# MSP432P401R register map
Vendor: Texas Instruments; File version: 3.220
Registers are 32-bit, read-write, reset 0x0 unless marked. A register's access mark holds for its fields unless they carry their own. Offsets are from the block's base; [hi:lo] are bit positions; {n}, {i} and the like mark numbered series.

## PSS
Base 0x40010800
0x00 PSSKEY reset 0xA596 — Key Register
  [15:0] PSSKEY — PSS control key
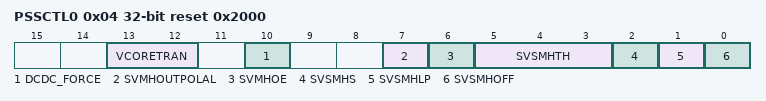
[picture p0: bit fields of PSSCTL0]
0x04 PSSCTL0 reset 0x2000 — Control 0 Register
  [13:12] VCORETRAN — Controls core voltage level transition time
    0=32 s / 100 mV; 1=64 s / 100 mV; 2=128 s / 100 mV (default); 3=256 s / 100 mV
  [10] DCDC_FORCE — Force DC-DC regulator operation
    0=DC-DC regulator operation not forced. Automatic fail-safe mechanism switches the core voltage regulator from DC-DC to LDO when the supply voltage falls below the minimum supply voltage necessary for DC-DC operation.; 1=DC-DC regulator operation forced. Automatic fail-safe mechanism is disabled and device continues to operate out of DC-DC regulator.
  [7] SVMHOUTPOLAL — SVMHOUT pin polarity active low
    0=SVMHOUT is active high. An error condition is signaled by a 1 at the SVMHOUT pin; 1=SVMHOUT is active low. An error condition is signaled by a 0 at the SVMHOUT pin
  [6] SVMHOE — SVSM high-side output enable
    0=SVSMHIFG bit is not output; 1=SVSMHIFG bit is output to the device SVMHOUT pin. The device-specific port logic must be configured accordingly
  [5:3] SVSMHTH — SVSM high-side reset voltage level
  [2] SVSMHS — Supply supervisor or monitor selection for the high-side
    0=Configure as SVSH; 1=Configure as SVMH
  [1] SVSMHLP — SVSM high-side low power normal performance mode
    0=Full performance mode. See the device-specific data sheet for response times.; 1=Low power normal performance mode in LPM3, LPM4, and LPMx.5, full performance in all other modes. See the device-specific data sheet for response times.
  [0] SVSMHOFF — SVSM high-side off
    0=The SVSMH is on; 1=The SVSMH is off
0x34 PSSIE — Interrupt Enable Register
  [1] SVSMHIE — High-side SVSM interrupt enable
    0=Interrupt disabled; 1=Interrupt enabled
0x38 PSSIFG ro — Interrupt Flag Register
  [1] SVSMHIFG — High-side SVSM interrupt flag
    on read: 0=No interrupt pending; 1=Interrupt due to SVSMH
0x3C PSSCLRIFG — Clear Interrupt Flag Register
  [1] CLRSVSMHIFG wo — SVSMH clear interrupt flag
    on write: 0=No effect; 1=Clear pending interrupt flag

## ITM
Base 0xE0000000
{0x0+4i} ITM_STIM{i} (i=0..31) — ITM Stimulus Port {i}
0xE00 ITM_TER — ITM Trace Enable Register
  [31:0] STIMENA — Bit mask to enable tracing on ITM stimulus ports. One bit per stimulus port.
0xE40 ITM_TPR — ITM Trace Privilege Register
  [3:0] PRIVMASK — Bit mask to enable tracing on ITM stimulus ports: bit [0] = stimulus ports [7:0], bit [1] = stimulus ports [15:8], bit [2] = stimulus ports [23:16], bit [3] = stimulus ports [31:24].
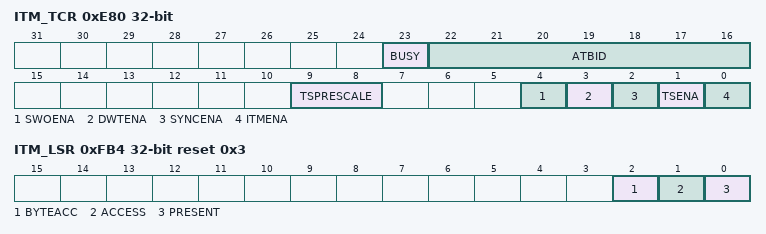
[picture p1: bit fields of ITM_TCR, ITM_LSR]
0xE80 ITM_TCR — ITM Trace Control Register
  [23] BUSY — Set when ITM events present and being drained.
  [22:16] ATBID — ATB ID for CoreSight system.
  [9:8] TSPRESCALE — TSPrescale Timestamp prescaler.
    0=en_0b00 (no prescaling); 1=en_0b01 (divide by 4); 2=en_0b10 (divide by 16); 3=en_0b11 (divide by 64)
  [4] SWOENA — Enables asynchronous clocking of the timestamp counter.
  [3] DWTENA — Enables the DWT stimulus.
  [2] SYNCENA — Enables sync packets for TPIU.
  [1] TSENA — Enables differential timestamps. Differential timestamps are emitted when a packet is written to the FIFO with a non-zero timestamp counter, and when the timestamp counter overflows. Timestamps are emitted during idle times after a fixed number of two million cycles. This provides a time reference for packets and inter-packet gaps. If SWOENA (bit [4]) is set, timestamps are triggered by activity on the internal trace bus only. In this case there is no regular timestamp output when the ITM is idle.
  [0] ITMENA — Enable ITM. This is the master enable, and must be set before ITM Stimulus and Trace Enable registers can be written.
0xEF8 ITM_IWR wo — ITM Integration Write Register
  [0] ATVALIDM — When the integration mode is set: 0 = ATVALIDM clear. 1 = ATVALIDM set.
    0=en_0b0 (ATVALIDM clear); 1=en_0b1 (ATVALIDM set)
0xF00 ITM_IMCR — ITM Integration Mode Control Register
  [0] INTEGRATION
    0=en_0b0 (ATVALIDM normal); 1=en_0b1 (ATVALIDM driven from Integration Write Register)
0xFB0 ITM_LAR wo — ITM Lock Access Register
  [31:0] LOCK_ACCESS — A privileged write of 0xC5ACCE55 enables more write access to Control Register 0xE00::0xFFC. An invalid write removes write access.
0xFB4 ITM_LSR ro reset 0x3 — ITM Lock Status Register
  [2] BYTEACC — You cannot implement 8-bit lock accesses.
  [1] ACCESS — Write access to component is blocked. All writes are ignored, reads are permitted.
  [0] PRESENT — Indicates that a lock mechanism exists for this component.
